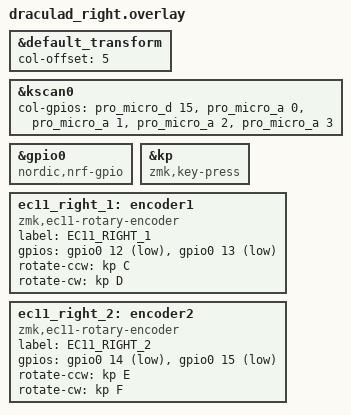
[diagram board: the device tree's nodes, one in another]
#include "draculad.dtsi"

&default_transform {
    col-offset = <5>;
};

&kscan0 {
    col-gpios =
        <&pro_micro_d 15 GPIO_ACTIVE_HIGH>,
        <&pro_micro_a 0 GPIO_ACTIVE_HIGH>,
        <&pro_micro_a 1 GPIO_ACTIVE_HIGH>,
        <&pro_micro_a 2 GPIO_ACTIVE_HIGH>,
        <&pro_micro_a 3 GPIO_ACTIVE_HIGH>;
};

&gpio0 {
    compatible = "nordic,nrf-gpio";
};

/* Define &kp or replace it with an appropriate label */
&kp {
    compatible = "zmk,key-press";
};

ec11_right_1: encoder1 {
    compatible = "zmk,ec11-rotary-encoder";
    label = "EC11_RIGHT_1";
    gpios = <&gpio0 12 GPIO_ACTIVE_LOW>, <&gpio0 13 GPIO_ACTIVE_LOW>;
    rotate-ccw = <&kp C>;  /* Check if &kp is valid */
    rotate-cw  = <&kp D>;  /* Check if &kp is valid */
};

ec11_right_2: encoder2 {
    compatible = "zmk,ec11-rotary-encoder";
    label = "EC11_RIGHT_2";
    gpios = <&gpio0 14 GPIO_ACTIVE_LOW>, <&gpio0 15 GPIO_ACTIVE_LOW>;
    rotate-ccw = <&kp E>;  /* Check if &kp is valid */
    rotate-cw  = <&kp F>;  /* Check if &kp is valid */
};
